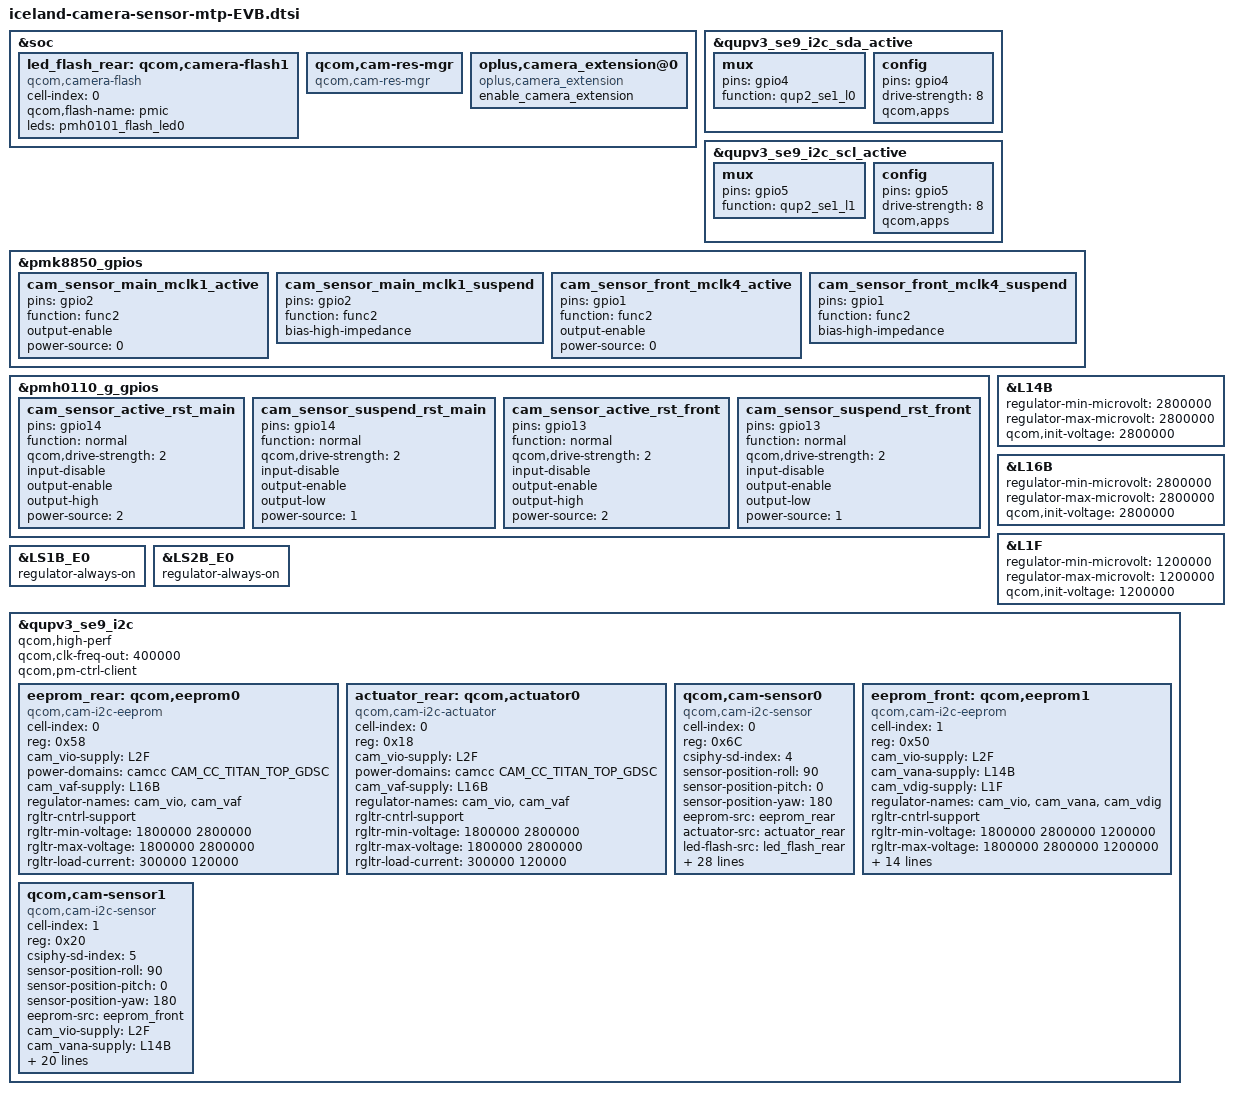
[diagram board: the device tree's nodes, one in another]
#include <dt-bindings/msm-camera.h>
#include "ftm_camera_settings.dtsi"

&soc {
	led_flash_rear: qcom,camera-flash1 {
		cell-index = <0>;
		compatible = "qcom,camera-flash";
		qcom,flash-name = "pmic";
		leds = <&pmh0101_flash_led0>;
		status = "ok";
	};
	qcom,cam-res-mgr {
		compatible = "qcom,cam-res-mgr";
		status = "ok";
	};
	oplus,camera_extension@0 {
		compatible = "oplus,camera_extension";
		enable_camera_extension;
		status = "ok";
	};
};

&qupv3_se9_i2c_sda_active {
 	mux {
 		pins = "gpio4";
 		function = "qup2_se1_l0";
 	};

 	config {
 		pins = "gpio4";
 		drive-strength = <8>;
 		/* qcom,i2c_pull; oplus remove*/
 		qcom,apps;
 	};
};

&qupv3_se9_i2c_scl_active {
 	mux {
 		pins = "gpio5";
 		function = "qup2_se1_l1";
 	};

 	config {
 		pins = "gpio5";
 		drive-strength = <8>;
 		/* qcom,i2c_pull; oplus remove*/
 		qcom,apps;
 	};
};

&pmk8850_gpios {
	cam_sensor_main_mclk1_active: cam_sensor_main_mclk1_active {
			pins = "gpio2";
			function = "func2";
			output-enable;
			power-source = <0>; /* 1.8 V */
   };
	cam_sensor_main_mclk1_suspend: cam_sensor_main_mclk1_suspend {
 			pins = "gpio2";
 			function = "func2";
 			bias-high-impedance;
   };
   	cam_sensor_front_mclk4_active: cam_sensor_front_mclk4_active {
			pins = "gpio1";
			function = "func2";
			output-enable;
			power-source = <0>; /* 1.8 V */
   };
	cam_sensor_front_mclk4_suspend: cam_sensor_front_mclk4_suspend {
 			pins = "gpio1";
 			function = "func2";
 			bias-high-impedance;
   };
};

&pmh0110_g_gpios {
	cam_sensor_active_rst_main: cam_sensor_active_rst_main {
		pins = "gpio14";
		function = "normal";
		qcom,drive-strength = <2>;
		input-disable;
		output-enable;
		output-high;
		power-source = <2>;/* 1.8 V */
	};

	cam_sensor_suspend_rst_main: cam_sensor_suspend_rst_main {
		pins = "gpio14";
		function = "normal";
		qcom,drive-strength = <2>;
		input-disable;
		output-enable;
		output-low;
		power-source = <1>;
	};

	cam_sensor_active_rst_front: cam_sensor_active_rst_front {
		pins = "gpio13";
		function = "normal";
		qcom,drive-strength = <2>;
		input-disable;
		output-enable;
		output-high;
		power-source = <2>;/* 1.8 V */
	};

	cam_sensor_suspend_rst_front: cam_sensor_suspend_rst_front {
		pins = "gpio13";
		function = "normal";
		qcom,drive-strength = <2>;
		input-disable;
		output-enable;
		output-low;
		power-source = <1>;
	};
};

&L14B {
  regulator-min-microvolt = <2800000>;
  regulator-max-microvolt = <2800000>;
  qcom,init-voltage = <2800000>;
};

&L16B {
  regulator-min-microvolt = <2800000>;
  regulator-max-microvolt = <2800000>;
  qcom,init-voltage = <2800000>;
};

&L1F {
  regulator-min-microvolt = <1200000>;
  regulator-max-microvolt = <1200000>;
  qcom,init-voltage = <1200000>;
};

&LS1B_E0 {
	regulator-always-on;
};


&LS2B_E0 {
	regulator-always-on;
};


/*
&pmh0101_gpios {
	ts_rst_1p2_active: ts-rst-1p2-active-state {
		pins = "gpio12";
		function = "paired";
		input-enable;
		output-disable;
		power-source = <2>;
	};
	ts_rst_1p8_active: ts-rst-1p8-active-state {
		pins = "gpio11";
		function = "paired";
		input-disable;
		output-enable;
		power-source = <1>;
	};
	ss_rst_1p2_active: ss-rst-1p2-active-state {
		pins = "gpio14";
		function = "paired";
		input-enable;
		output-disable;
		power-source = <2>;
	};
	ss_rst_1p8_active: ss-rst-1p8-active-state {
		pins = "gpio13";
		function = "paired";
		input-disable;
		output-enable;
		power-source = <1>;
	};
};
*/

&qupv3_se9_i2c {
	status = "ok";
	qcom,high-perf;
	qcom,clk-freq-out = <400000>;
	qcom,pm-ctrl-client;

	eeprom_rear: qcom,eeprom0 {
		cell-index = <0>;
		reg = <0x58>;
		compatible = "qcom,cam-i2c-eeprom";
		cam_vio-supply = <&L2F>;
		power-domains = <&camcc CAM_CC_TITAN_TOP_GDSC>;
		cam_vaf-supply = <&L16B>;
		regulator-names ="cam_vio","cam_vaf";
		rgltr-cntrl-support;
		rgltr-min-voltage = <1800000 2800000>;
		rgltr-max-voltage = <1800000 2800000>;
		rgltr-load-current = <300000 120000>;
		status = "ok";
	};

	actuator_rear: qcom,actuator0 {
		cell-index = <0>;
		reg = <0x18>;
		compatible = "qcom,cam-i2c-actuator";
		cam_vio-supply = <&L2F>;
		power-domains = <&camcc CAM_CC_TITAN_TOP_GDSC>;
		cam_vaf-supply = <&L16B>;
		regulator-names ="cam_vio","cam_vaf";
		rgltr-cntrl-support;
		rgltr-min-voltage = <1800000 2800000>;
		rgltr-max-voltage = <1800000 2800000>;
		rgltr-load-current = <300000 120000>;
		status = "ok";
	};

    //main camera
	qcom,cam-sensor0 {
		cell-index = <0>;
		reg = <0x6C>;
		compatible = "qcom,cam-i2c-sensor";
		csiphy-sd-index = <4>;
		sensor-position-roll = <90>;
		sensor-position-pitch = <0>;
		sensor-position-yaw = <180>;
		eeprom-src = <&eeprom_rear>;
		actuator-src = <&actuator_rear>;
		led-flash-src = <&led_flash_rear>;
		cam_vana-supply = <&L14B>;
		cam_vdig-supply = <&L1F>;
		cam_vio-supply = <&L2F>;
		power-domains = <&camcc CAM_CC_TITAN_TOP_GDSC>;
		cam_vaf-supply = <&L16B>;
		regulator-names = "cam_vana", "cam_vdig","cam_vio","cam_vaf";
		rgltr-cntrl-support;
		rgltr-min-voltage = <2800000 1200000 1800000 2800000>;
		rgltr-max-voltage = <2800000 1200000 1800000 2800000>;
		rgltr-load-current = <600000 120000 300000 120000>;
		gpio-no-mux = <0>;
		pinctrl-names = "cam_default", "cam_suspend";
		pinctrl-0 = <&cam_sensor_main_mclk1_active
				&cam_sensor_active_rst_main>;
		pinctrl-1 = <&cam_sensor_main_mclk1_suspend
				&cam_sensor_suspend_rst_main>;
		gpios = <&pmh0110_g_gpios 14 0>;
		gpio-reset = <0>;
		gpio-req-tbl-num = <0>;
		gpio-req-tbl-flags = <0>;
		gpio-req-tbl-label = "CAM_RESET1_1P8";
		clocks = <&rpmhcc RPMH_DIV_CLK1>;
		clock-names = "cam_clk";
		clock-cntl-level = "nominal";
		clock-rates = <19200000>;
		//is-support-laser = <1>;
		//enable_qsc_write_in_advance = <1>;
		//qsc_reg_addr = <0x24C0>;
		//eeprom_slave_addr = <0xA0>;
		//qsc_data_size = <2304>;
		//write_qsc_addr = <0x5800>;
		ftm_setting_compatible = <'R' 0x3107 2 2 0xc658>; // expect camera_3107_c658
		status = "ok";
	};

	eeprom_front: qcom,eeprom1 {
		cell-index = <1>;
		reg = <0x50>;
		compatible = "qcom,cam-i2c-eeprom";
		cam_vio-supply = <&L2F>;
		cam_vana-supply = <&L14B>;
		cam_vdig-supply = <&L1F>;
		regulator-names = "cam_vio", "cam_vana","cam_vdig";
		rgltr-cntrl-support;
		rgltr-min-voltage = <1800000 2800000 1200000>;
		rgltr-max-voltage = <1800000 2800000 1200000>;
		rgltr-load-current = <300000 600000 600000>;
		gpio-no-mux = <0>;
		pinctrl-names = "cam_default", "cam_suspend";
		pinctrl-0 = <&cam_sensor_front_mclk4_active
				 &cam_sensor_active_rst_front>;
		pinctrl-1 = <&cam_sensor_front_mclk4_suspend
				 &cam_sensor_suspend_rst_front>;
		gpios = <&pmh0110_g_gpios 13 0>;
		gpio-reset = <0>;
		gpio-req-tbl-num = <0>;
		gpio-req-tbl-flags = <0>;
		gpio-req-tbl-label = "CAM_RESET4";
		clocks = <&rpmhcc RPMH_DIV_CLK1>;
		clock-names = "cam_clk";
		clock-cntl-level = "nominal";
		clock-rates = <19200000>;
		status = "ok";
	};

	qcom,cam-sensor1 {
		cell-index = <1>;
		reg = <0x20>;
		compatible = "qcom,cam-i2c-sensor";
		csiphy-sd-index = <5>;
		sensor-position-roll = <90>;
		sensor-position-pitch = <0>;
		sensor-position-yaw = <180>;
		eeprom-src = <&eeprom_front>;
		cam_vio-supply = <&L2F>;
		cam_vana-supply = <&L14B>;
		cam_vdig-supply = <&L1F>;
		regulator-names = "cam_vio", "cam_vana","cam_vdig";
		rgltr-cntrl-support;
		rgltr-min-voltage = <1800000 2800000 1200000>;
		rgltr-max-voltage = <1800000 2800000 1200000>;
		rgltr-load-current = <300000 600000 600000>;
		gpio-no-mux = <0>;
		pinctrl-names = "cam_default", "cam_suspend";
		pinctrl-0 = <&cam_sensor_front_mclk4_active
				 &cam_sensor_active_rst_front>;
		pinctrl-1 = <&cam_sensor_front_mclk4_suspend
				 &cam_sensor_suspend_rst_front>;
		gpios = <&pmh0110_g_gpios 13 0>;
		gpio-reset = <0>;
		gpio-req-tbl-num = <0>;
		gpio-req-tbl-flags = <0>;
		gpio-req-tbl-label = "CAM_RESET4";
		clocks = <&rpmhcc RPMH_DIV_CLK1>;
		clock-names = "cam_clk";
		clock-cntl-level = "nominal";
		clock-rates = <19200000>;
		ftm_setting_compatible = <'R' 0x3107 2 2 0xd154>; // expect camera_3107_d154
		status = "ok";
	};
};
